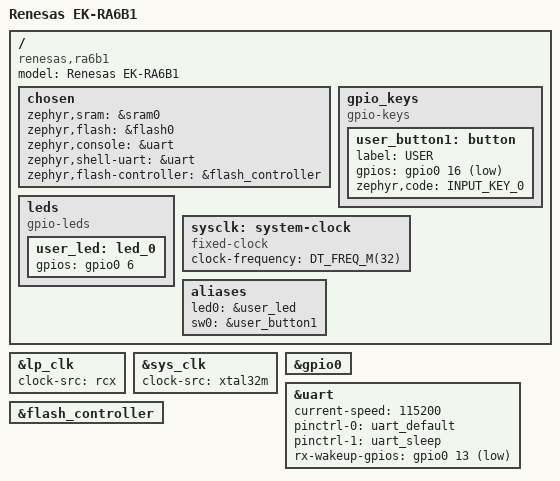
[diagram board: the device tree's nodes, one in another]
/*
 * SPDX-FileCopyrightText: 2026 Renesas Electronics Corporation
 * SPDX-License-Identifier: Apache-2.0
 */

#include <dt-bindings/gpio/gpio.h>
#include <zephyr/dt-bindings/input/input-event-codes.h>

#include "ek_ra6b1-pinctrl.dtsi"

/ {
	model = "Renesas EK-RA6B1";
	compatible = "renesas,ra6b1", "renesas,ra";

	chosen {
		zephyr,sram = &sram0;
		zephyr,flash = &flash0;
		zephyr,console = &uart;
		zephyr,shell-uart = &uart;
		zephyr,flash-controller = &flash_controller;
	};

	gpio_keys {
		compatible = "gpio-keys";

		user_button1: button {
			label = "USER";
			gpios = <&gpio0 16 (GPIO_ACTIVE_LOW | GPIO_PULL_UP)>;
			zephyr,code = <INPUT_KEY_0>;
		};
	};

	leds {
		compatible = "gpio-leds";

		user_led: led_0 {
			gpios = <&gpio0 6 GPIO_ACTIVE_HIGH>;
		};
	};

	sysclk: system-clock {
		compatible = "fixed-clock";
		clock-frequency = <DT_FREQ_M(32)>;
		#clock-cells = <0>;
	};

	aliases {
		led0 = &user_led;
		sw0 = &user_button1;
	};
};

&lp_clk {
	clock-src = <&rcx>;
};

&sys_clk {
	clock-src = <&xtal32m>;
};

&gpio0 {
	status = "okay";
};

&uart {
	current-speed = <115200>;
	status = "okay";
	pinctrl-0 = <&uart_default>;
	pinctrl-1 = <&uart_sleep>;
	pinctrl-names = "default", "sleep";
	rx-wakeup-gpios = <&gpio0 13 GPIO_ACTIVE_LOW>;
};

&flash_controller {
	status = "okay";
};
